# PAC55XX register map
Vendor: Qorvo, Inc.; Series: PAC55XX; File version: 1.0
CPU: CM4 r0p1, little endian, MPU, FPU, vendor SysTick, 3 interrupt priority bits
Registers are 32-bit, read-write, reset 0x0 unless marked. A register's access mark holds for its fields unless they carry their own. Offsets are from the block's base; [hi:lo] are bit positions; {n}, {i} and the like mark numbered series.

## ADC — Analog to Digital Converter (ADC) and Dynamic Triggering and Sampling Engine (DTSE)
Base 0x40000000
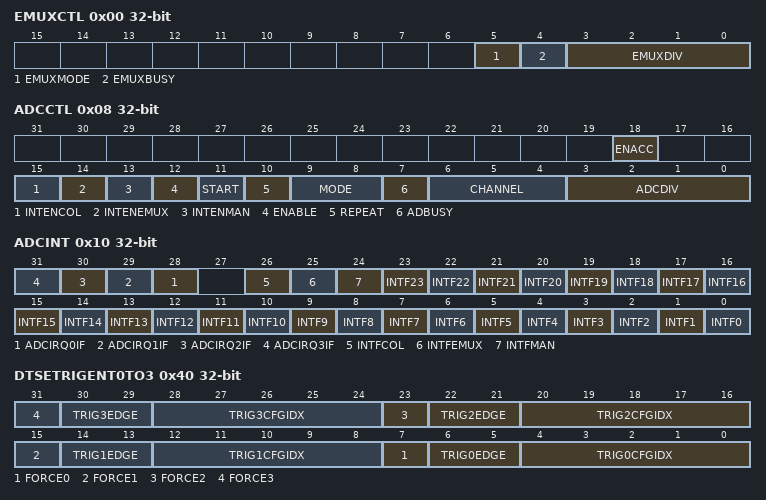
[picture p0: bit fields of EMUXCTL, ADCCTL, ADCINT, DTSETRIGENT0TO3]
0x00 EMUXCTL — EMUX Control
  [5] EMUXMODE
    0=DATA_FROM_EMUXDATA (Write EMUX data from EMUXDATA register); 1=DATA_FROM_DTSE (Write EMUX data from DTSE sequencer commands)
  [4] EMUXBUSY ro
  [3:0] EMUXDIV — EMUX Clock Divider
    {v}=SCLK{v+1} (v=0..14)
0x04 EMUXDATA
  [7:0] EMUXDATA — Write data onto the EMUX
0x08 ADCCTL — ADC Control
  [18] ENACC — ADC Accuracy Mode Enable
  [15] INTENCOL — Sequence Collision Interrupt Enable
  [14] INTENEMUX — EMUX Complete Interrupt Enable
  [13] INTENMAN — Manual Conversion Complete Interrupt Enable
  [12] ENABLE — ADC Enable
  [11] START wo — ADC Start
  [10] REPEAT — ADC Repeat
  [9:8] MODE — ADC Mode
    0=MANUAL (Manual mode); 1=DTSE (DTSE mode)
  [7] ADBUSY ro — ADC Busy
  [6:4] CHANNEL — ADC Channel Select
  [3:0] ADCDIV — ADC Clock Divider
    {v}=SCLK{v+1} (v=0..15)
0x0C ADCRES — ADC Result
  [11:0] ADCRES ro — ADC Conversion Result (manual mode)
0x10 ADCINT — ADC Interrupt Control
  [n+28] ADCIRQ{n}IF wo (n=0..3) — ADCIRQ{n} Interrupt Flag
  [26] INTFCOL wo — DTSE Sequence Collision Interrupt Flag
  [25] INTFEMUX wo — DTSE EMUX Complete Interrupt Flag
  [24] INTFMAN wo — DTSE Manual Conversion Complete Interrupt Flag
  [n] INTF{n} wo (n=0..23) — DTSE Sequence {n} Interrupt Flag
0x40 DTSETRIGENT0TO3 — DTSE Trigger Entry 0 to 3
  [8n+7] FORCE{n} wo (n=0..3) — Force Trigger {n}
  [8n+6:8n+5] TRIG{n}EDGE (n=0..3) — DTSE Trigger {n} Edge Configuration
    1=RISING_EDGE; 2=FALLING_EDGE; 3=BOTH_EDGES
  [8n+4:8n] TRIG{n}CFGIDX (n=0..3) — DTSE Trigger {n} Sequence Configuration Entry Index
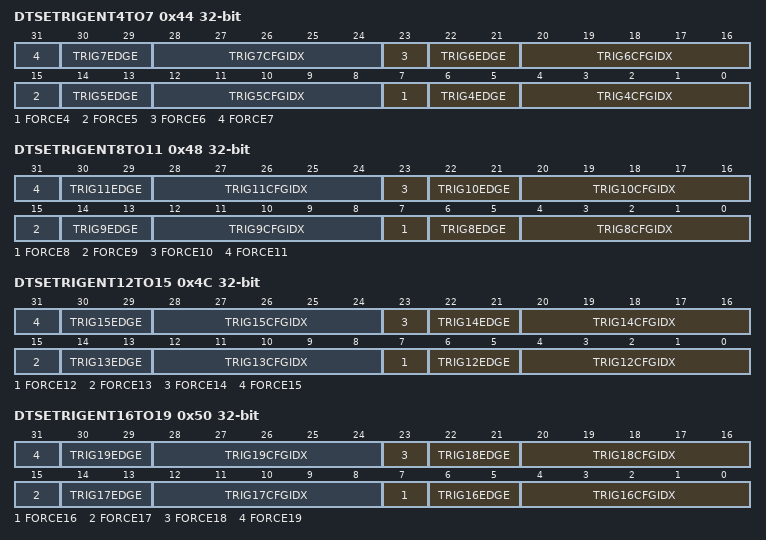
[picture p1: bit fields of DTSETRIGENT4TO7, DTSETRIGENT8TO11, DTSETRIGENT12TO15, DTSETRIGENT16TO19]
0x44 DTSETRIGENT4TO7 — DTSE Trigger Entry 4 to 7
  [8n-25] FORCE{n} wo (n=4..7) — Force Trigger {n}
  [8n-26:8n-27] TRIG{n}EDGE (n=4..7) — DTSE Trigger {n} Edge Configuration
    1=RISING_EDGE; 2=FALLING_EDGE; 3=BOTH_EDGES
  [8n-28:8n-32] TRIG{n}CFGIDX (n=4..7) — DTSE Trigger {n} Sequence Configuration Entry Index
0x48 DTSETRIGENT8TO11 — DTSE Trigger Entry 8 to 11
  [8n-57] FORCE{n} wo (n=8..11) — Force Trigger {n}
  [8n-58:8n-59] TRIG{n}EDGE (n=8..11) — DTSE Trigger {n} Edge Configuration
    1=RISING_EDGE; 2=FALLING_EDGE; 3=BOTH_EDGES
  [8n-60:8n-64] TRIG{n}CFGIDX (n=8..11) — DTSE Trigger {n} Sequence Configuration Entry Index
0x4C DTSETRIGENT12TO15 — DTSE Trigger Entry 12 to 15
  [8n-89] FORCE{n} wo (n=12..15) — Force Trigger {n}
  [8n-90:8n-91] TRIG{n}EDGE (n=12..15) — DTSE Trigger {n} Edge Configuration
    1=RISING_EDGE; 2=FALLING_EDGE; 3=BOTH_EDGES
  [8n-92:8n-96] TRIG{n}CFGIDX (n=12..15) — DTSE Trigger {n} Sequence Configuration Entry Index
0x50 DTSETRIGENT16TO19 — DTSE Trigger Entry 16 to 19
  [8n-121] FORCE{n} wo (n=16..19) — Force Trigger {n}
  [8n-122:8n-123] TRIG{n}EDGE (n=16..19) — DTSE Trigger {n} Edge Configuration
    1=RISING_EDGE; 2=FALLING_EDGE; 3=BOTH_EDGES
  [8n-124:8n-128] TRIG{n}CFGIDX (n=16..19) — DTSE Trigger {n} Sequence Configuration Entry Index
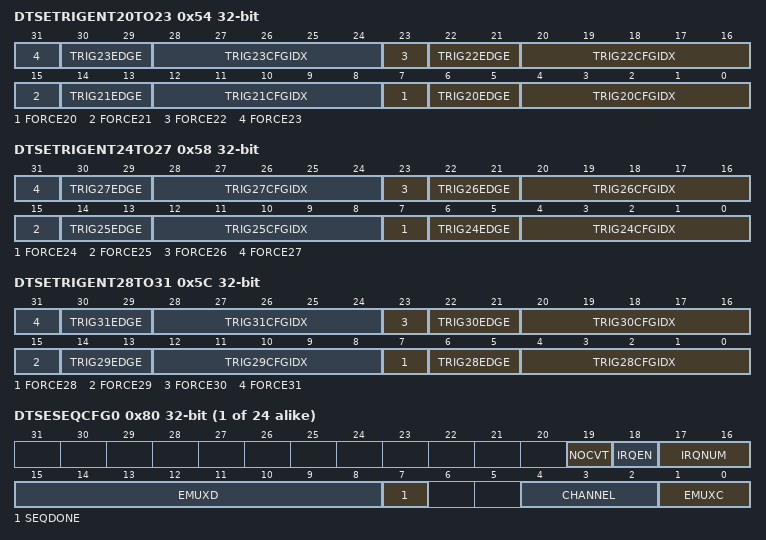
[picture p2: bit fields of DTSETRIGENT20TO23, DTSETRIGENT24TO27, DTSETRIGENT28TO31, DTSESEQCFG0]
0x54 DTSETRIGENT20TO23 — DTSE Trigger Entry 20 to 23
  [8n-153] FORCE{n} wo (n=20..23) — Force Trigger {n}
  [8n-154:8n-155] TRIG{n}EDGE (n=20..23) — DTSE Trigger {n} Edge Configuration
    1=RISING_EDGE; 2=FALLING_EDGE; 3=BOTH_EDGES
  [8n-156:8n-160] TRIG{n}CFGIDX (n=20..23) — DTSE Trigger {n} Sequence Configuration Entry Index
0x58 DTSETRIGENT24TO27 — DTSE Trigger Entry 24 to 27
  [8n-185] FORCE{n} wo (n=24..27) — Force Trigger {n}
  [8n-186:8n-187] TRIG{n}EDGE (n=24..27) — DTSE Trigger {n} Edge Configuration
    1=RISING_EDGE; 2=FALLING_EDGE; 3=BOTH_EDGES
  [8n-188:8n-192] TRIG{n}CFGIDX (n=24..27) — DTSE Trigger {n} Sequence Configuration Entry Index
0x5C DTSETRIGENT28TO31 — DTSE Trigger Entry 28 to 31
  [8n-217] FORCE{n} wo (n=28..31) — Force Trigger {n}
  [8n-218:8n-219] TRIG{n}EDGE (n=28..31) — DTSE Trigger {n} Edge Configuration
    1=RISING_EDGE; 2=FALLING_EDGE; 3=BOTH_EDGES
  [8n-220:8n-224] TRIG{n}CFGIDX (n=28..31) — DTSE Trigger {n} Sequence Configuration Entry Index
{0x80+4i} DTSESEQCFG{i} (i=0..23) — DTSE Sequence Configuration {i}
  [19] NOCVT — No ADC conversion
  [18] IRQEN — Assert IRQ after converting this sequence
  [17:16] IRQNUM — IRQ Number to assert
  [15:8] EMUXD — EMUX Data
  [7] SEQDONE — Final sequence of series
  [4:2] CHANNEL
  [1:0] EMUXC — EMUX Control
    0=NO_EMUX_CMD (Do not send EMUX command); 1=EMUX_CMD_BEFORE_SAMPLE (Send EMUX command before sample and hold); 2=EMUX_CMD_AFTER_CONVERSION (Send EMUX command after conversion is complete)
{0x200+4i} DTSERES{i} (i=0..23) — DTSE Result {i}
  [11:0] RES ro — DTSE Conversion Result
